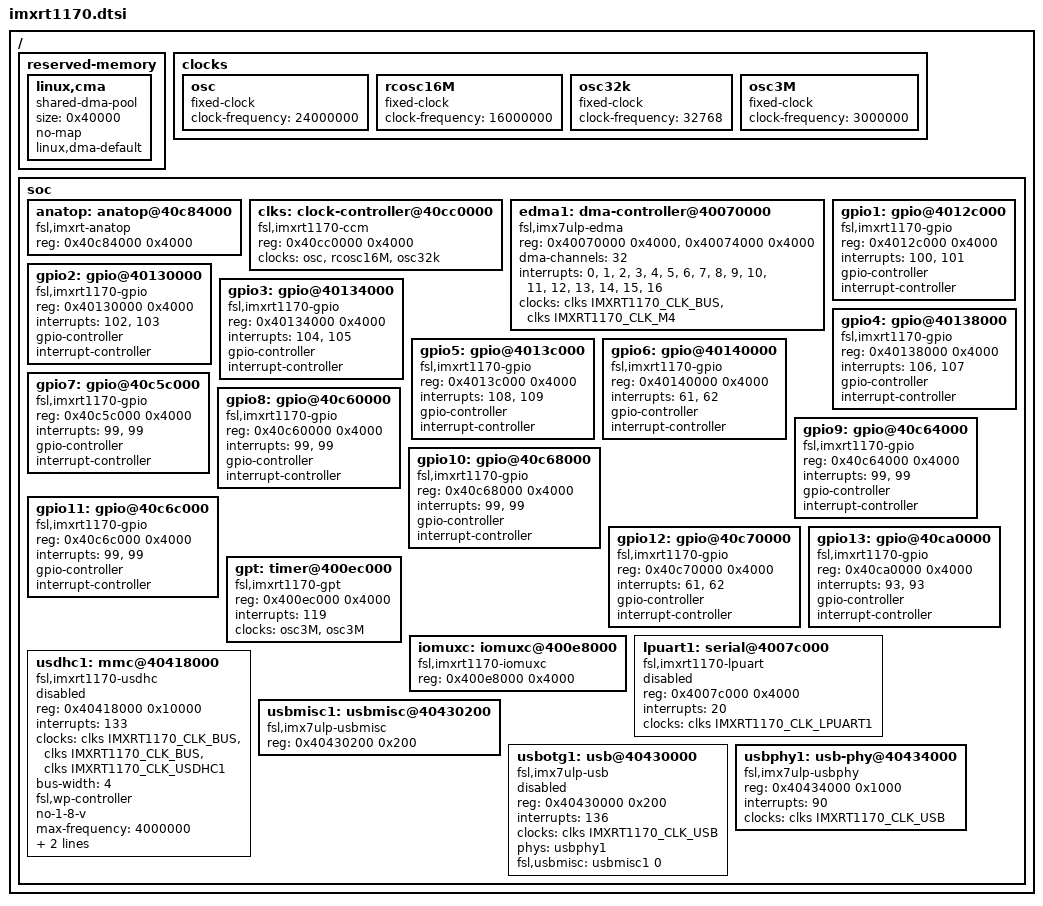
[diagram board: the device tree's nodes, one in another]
// SPDX-License-Identifier: (GPL-2.0+ OR BSD-3-Clause)
/*
 * Copyright (C) 2022
 * Author(s):  Jesse Taube <Mr.Bossman075@gmail.com>
 */

#include "armv7-m.dtsi"
#include <dt-bindings/interrupt-controller/arm-gic.h>
#include <dt-bindings/clock/imxrt1170-clock.h>
#include <dt-bindings/gpio/gpio.h>

/ {
	#address-cells = <1>;
	#size-cells = <1>;

	reserved-memory {
		#address-cells = <1>;
		#size-cells = <1>;
		ranges;

		linux,cma {
			compatible = "shared-dma-pool";
			size = <0x40000>;
			no-map;
			linux,dma-default;
		};
	};

	clocks {
		osc: osc {
			compatible = "fixed-clock";
			#clock-cells = <0>;
			clock-frequency = <24000000>;
		};

		rcosc16M: rcosc16M {
			compatible = "fixed-clock";
			#clock-cells = <0>;
			clock-frequency = <16000000>;
		};

		osc32k: osc32k {
			compatible = "fixed-clock";
			#clock-cells = <0>;
			clock-frequency = <32768>;
		};

		osc3M: osc3M {
			compatible = "fixed-clock";
			#clock-cells = <0>;
			clock-frequency = <3000000>;
		};
	};

	soc {
		anatop: anatop@40c84000 {
			compatible = "fsl,imxrt-anatop";
			reg = <0x40c84000 0x4000>;
		};

		clks: clock-controller@40cc0000 {
			compatible = "fsl,imxrt1170-ccm";
			reg = <0x40cc0000 0x4000>;
			clocks = <&osc>, <&rcosc16M>, <&osc32k>;
			clock-names = "osc", "rcosc16M", "osc32k";
			#clock-cells = <1>;
		};

		edma1: dma-controller@40070000 {
			#dma-cells = <2>;
			compatible = "fsl,imx7ulp-edma";
			reg = <0x40070000 0x4000>,
				<0x40074000 0x4000>;
			dma-channels = <32>;
			interrupts = <0>, <1>, <2>, <3>, <4>, <5>, <6>, <7>, <8>,
				<9>, <10>, <11>, <12>, <13>, <14>, <15>, <16>;
			clock-names = "dma", "dmamux0";
			clocks = <&clks IMXRT1170_CLK_BUS>,
				 <&clks IMXRT1170_CLK_M4>;
		};

		gpio1: gpio@4012c000 {
			compatible = "fsl,imxrt1170-gpio", "fsl,imx35-gpio";
			reg = <0x4012c000 0x4000>;
			interrupts = <100>, <101>;
			gpio-controller;
			#gpio-cells = <2>;
			interrupt-controller;
			#interrupt-cells = <2>;
		};

		gpio2: gpio@40130000 {
			compatible = "fsl,imxrt1170-gpio", "fsl,imx35-gpio";
			reg = <0x40130000 0x4000>;
			interrupts = <102>, <103>;
			gpio-controller;
			#gpio-cells = <2>;
			interrupt-controller;
			#interrupt-cells = <2>;
		};

		gpio3: gpio@40134000 {
			compatible = "fsl,imxrt1170-gpio", "fsl,imx35-gpio";
			reg = <0x40134000 0x4000>;
			interrupts = <104>, <105>;
			gpio-controller;
			#gpio-cells = <2>;
			interrupt-controller;
			#interrupt-cells = <2>;
		};

		gpio4: gpio@40138000 {
			compatible = "fsl,imxrt1170-gpio", "fsl,imx35-gpio";
			reg = <0x40138000 0x4000>;
			interrupts = <106>, <107>;
			gpio-controller;
			#gpio-cells = <2>;
			interrupt-controller;
			#interrupt-cells = <2>;
		};

		gpio5: gpio@4013c000 {
			compatible = "fsl,imxrt1170-gpio", "fsl,imx35-gpio";
			reg = <0x4013c000 0x4000>;
			interrupts = <108>, <109>;
			gpio-controller;
			#gpio-cells = <2>;
			interrupt-controller;
			#interrupt-cells = <2>;
		};

		gpio6: gpio@40140000 {
			compatible = "fsl,imxrt1170-gpio", "fsl,imx35-gpio";
			reg = <0x40140000 0x4000>;
			interrupts = <61>, <62>;
			gpio-controller;
			#gpio-cells = <2>;
			interrupt-controller;
			#interrupt-cells = <2>;
		};

		gpio7: gpio@40c5c000 {
			compatible = "fsl,imxrt1170-gpio", "fsl,imx35-gpio";
			reg = <0x40c5c000 0x4000>;
			interrupts = <99>, <99>;
			gpio-controller;
			#gpio-cells = <2>;
			interrupt-controller;
			#interrupt-cells = <2>;
		};

		gpio8: gpio@40c60000 {
			compatible = "fsl,imxrt1170-gpio", "fsl,imx35-gpio";
			reg = <0x40c60000 0x4000>;
			interrupts = <99>, <99>;
			gpio-controller;
			#gpio-cells = <2>;
			interrupt-controller;
			#interrupt-cells = <2>;
		};

		gpio9: gpio@40c64000 {
			compatible = "fsl,imxrt1170-gpio", "fsl,imx35-gpio";
			reg = <0x40c64000 0x4000>;
			interrupts = <99>, <99>;
			gpio-controller;
			#gpio-cells = <2>;
			interrupt-controller;
			#interrupt-cells = <2>;
		};

		gpio10: gpio@40c68000 {
			compatible = "fsl,imxrt1170-gpio", "fsl,imx35-gpio";
			reg = <0x40c68000 0x4000>;
			interrupts = <99>, <99>;
			gpio-controller;
			#gpio-cells = <2>;
			interrupt-controller;
			#interrupt-cells = <2>;
		};

		gpio11: gpio@40c6c000 {
			compatible = "fsl,imxrt1170-gpio", "fsl,imx35-gpio";
			reg = <0x40c6c000 0x4000>;
			interrupts = <99>, <99>;
			gpio-controller;
			#gpio-cells = <2>;
			interrupt-controller;
			#interrupt-cells = <2>;
		};

		gpio12: gpio@40c70000 {
			compatible = "fsl,imxrt1170-gpio", "fsl,imx35-gpio";
			reg = <0x40c70000 0x4000>;
			interrupts = <61>, <62>;
			gpio-controller;
			#gpio-cells = <2>;
			interrupt-controller;
			#interrupt-cells = <2>;
		};

		gpio13: gpio@40ca0000 {
			compatible = "fsl,imxrt1170-gpio", "fsl,imx35-gpio";
			reg = <0x40ca0000 0x4000>;
			interrupts = <93>, <93>;
			gpio-controller;
			#gpio-cells = <2>;
			interrupt-controller;
			#interrupt-cells = <2>;
		};

		gpt: timer@400ec000 {
			compatible = "fsl,imxrt1170-gpt", "fsl,imx6dl-gpt";
			reg = <0x400ec000 0x4000>;
			interrupts = <119>;
			clocks = <&osc3M>, <&osc3M>;
			clock-names = "ipg", "per";
		};

		iomuxc: iomuxc@400e8000 {
			compatible = "fsl,imxrt1170-iomuxc";
			reg = <0x400e8000 0x4000>;
		};

		lpuart1: serial@4007c000 {
			compatible = "fsl,imxrt1170-lpuart", "fsl,imxrt1050-lpuart";
			reg = <0x4007c000 0x4000>;
			interrupts = <20>;
			clocks = <&clks IMXRT1170_CLK_LPUART1>;
			clock-names = "ipg";
			status = "disabled";
		};

		usdhc1: mmc@40418000 {
			compatible = "fsl,imxrt1170-usdhc", "fsl,imxrt1050-usdhc";
			reg = <0x40418000 0x10000>;
			interrupts = <133>;
			clocks = <&clks IMXRT1170_CLK_BUS>,
				<&clks IMXRT1170_CLK_BUS>,
				<&clks IMXRT1170_CLK_USDHC1>;
			clock-names = "ipg", "ahb", "per";
			bus-width = <4>;
			fsl,wp-controller;
			no-1-8-v;
			max-frequency = <4000000>;
			fsl,tuning-start-tap = <20>;
			fsl,tuning-step= <2>;
			status = "disabled";
		};

		usbmisc1: usbmisc@40430200 {
			compatible = "fsl,imx7ulp-usbmisc";
			#index-cells = <1>;
			reg = <0x40430200 0x200>;
		};

		usbotg1: usb@40430000 {
			compatible = "fsl,imx7ulp-usb";
			reg = <0x40430000 0x200>;
			interrupts = <136>;
			clocks = <&clks IMXRT1170_CLK_USB>;
			phys = <&usbphy1>;
			fsl,usbmisc = <&usbmisc1 0>;
			status = "disabled";
		};

		usbphy1: usb-phy@40434000 {
			compatible = "fsl,imx7ulp-usbphy";
			reg = <0x40434000 0x1000>;
			interrupts = <90>;
			clocks = <&clks IMXRT1170_CLK_USB>;
			#phy-cells = <0>;
		};

	};
};
